AUTOSAR XML (schema 4-3-0)
package /CanCom
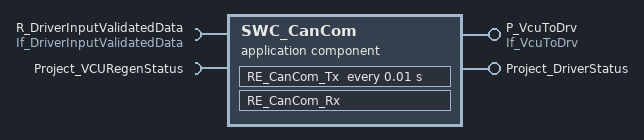
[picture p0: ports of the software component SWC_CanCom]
  application sw component type SWC_CanCom
    provide port P_VcuToDrv: provided-com-specs=[RegenLevel, RegenEnable, LimitReason], provided-interface=If_VcuToDrv
    require port R_DriverInputValidatedData: required-com-specs=[BrakeSw, AccelSw, SocLevel, VehicleSpeed, DriverInputFault], required-interface=If_DriverInputValidatedData
    provide port Project_DriverStatus: provided-interface=Project_DriverStatus
      provided-com-specs:
        data-element=VehicleSpeed, network-representation=compu-method=ISignal_Project_DriverStatus_VehicleSpeed
        data-element=AccelSw, network-representation=compu-method=ISignal_Project_DriverStatus_AccelSw
        data-element=DriverInputFault, network-representation=compu-method=ISignal_Project_DriverStatus_DriverInputFault
        data-element=SocLevel, network-representation=compu-method=ISignal_Project_DriverStatus_SocLevel
        data-element=AliveCounter, network-representation=compu-method=ISignal_Project_DriverStatus_AliveCounter
        data-element=BrakeSw, network-representation=compu-method=ISignal_Project_DriverStatus_BrakeSw
    require port Project_VCURegenStatus: required-interface=Project_VCURegenStatus
      required-com-specs:
        data-element=RegenEnable, network-representation=compu-method=ISignal_Project_VCURegenStatus_RegenEnable
        data-element=LimitReason, network-representation=compu-method=ISignal_Project_VCURegenStatus_LimitReason
        data-element=RegenLevel, network-representation=compu-method=ISignal_Project_VCURegenStatus_RegenLevel
    behavior InternalBehavior
      timing event TE_RE_CanCom_Tx: start-on-event=RE_CanCom_Tx, period=0.01
      data received event DRE_RE_CanCom_Rx_Project_VCURegenStatus_RegenEnable: start-on-event=RE_CanCom_Rx, data=Project_VCURegenStatus.RegenEnable
      data received event DRE_RE_CanCom_Rx_Project_VCURegenStatus_LimitReason: start-on-event=RE_CanCom_Rx, data=Project_VCURegenStatus.LimitReason
      data received event DRE_RE_CanCom_Rx_Project_VCURegenStatus_RegenLevel: start-on-event=RE_CanCom_Rx, data=Project_VCURegenStatus.RegenLevel
      runnable RE_CanCom_Tx: symbol=CanCom_Tx_func
        data-receive-point-by-arguments:
          5 x access, all with scope=COMMUNICATION-INTER-ECU:
            DRPBA_RE_CanCom_Tx_R_DriverInputValidatedData_AccelSw: accessed-variable=R_DriverInputValidatedData.AccelSw
            DRPBA_RE_CanCom_Tx_R_DriverInputValidatedData_BrakeSw: accessed-variable=R_DriverInputValidatedData.BrakeSw
            DRPBA_RE_CanCom_Tx_R_DriverInputValidatedData_DriverInputFault: accessed-variable=R_DriverInputValidatedData.DriverInputFault
            DRPBA_RE_CanCom_Tx_R_DriverInputValidatedData_SocLevel: accessed-variable=R_DriverInputValidatedData.SocLevel
            DRPBA_RE_CanCom_Tx_R_DriverInputValidatedData_VehicleSpeed: accessed-variable=R_DriverInputValidatedData.VehicleSpeed
        data-send-points:
          9 x access, all with scope=COMMUNICATION-INTER-ECU:
            DSP_RE_CanCom_Tx_Project_DriverStatus_AccelSw: accessed-variable=Project_DriverStatus.AccelSw
            DSP_RE_CanCom_Tx_Project_DriverStatus_AliveCounter: accessed-variable=Project_DriverStatus.AliveCounter
            DSP_RE_CanCom_Tx_Project_DriverStatus_BrakeSw: accessed-variable=Project_DriverStatus.BrakeSw
            DSP_RE_CanCom_Tx_Project_DriverStatus_DriverInputFault: accessed-variable=Project_DriverStatus.DriverInputFault
            DSP_RE_CanCom_Tx_Project_DriverStatus_SocLevel: accessed-variable=Project_DriverStatus.SocLevel
            DSP_RE_CanCom_Tx_Project_DriverStatus_VehicleSpeed: accessed-variable=Project_DriverStatus.VehicleSpeed
            DSP_RE_CanCom_Tx_P_VcuToDrv_LimitReason: accessed-variable=P_VcuToDrv.LimitReason
            DSP_RE_CanCom_Tx_P_VcuToDrv_RegenEnable: accessed-variable=P_VcuToDrv.RegenEnable
            DSP_RE_CanCom_Tx_P_VcuToDrv_RegenLevel: accessed-variable=P_VcuToDrv.RegenLevel
      runnable RE_CanCom_Rx: symbol=CanCom_Rx_func
        data-receive-point-by-arguments:
          8 x access, all with scope=COMMUNICATION-INTER-ECU:
            DRPBA_RE_CanCom_Rx_Project_VCURegenStatus_LimitReason: accessed-variable=Project_VCURegenStatus.LimitReason
            DRPBA_RE_CanCom_Rx_Project_VCURegenStatus_RegenEnable: accessed-variable=Project_VCURegenStatus.RegenEnable
            DRPBA_RE_CanCom_Rx_Project_VCURegenStatus_RegenLevel: accessed-variable=Project_VCURegenStatus.RegenLevel
            DRPBA_RE_CanCom_Rx_R_DriverInputValidatedData_AccelSw: accessed-variable=R_DriverInputValidatedData.AccelSw
            DRPBA_RE_CanCom_Rx_R_DriverInputValidatedData_BrakeSw: accessed-variable=R_DriverInputValidatedData.BrakeSw
            DRPBA_RE_CanCom_Rx_R_DriverInputValidatedData_DriverInputFault: accessed-variable=R_DriverInputValidatedData.DriverInputFault
            DRPBA_RE_CanCom_Rx_R_DriverInputValidatedData_SocLevel: accessed-variable=R_DriverInputValidatedData.SocLevel
            DRPBA_RE_CanCom_Rx_R_DriverInputValidatedData_VehicleSpeed: accessed-variable=R_DriverInputValidatedData.VehicleSpeed
        data-send-points:
          access DSP_RE_CanCom_Rx_P_VcuToDrv_LimitReason: accessed-variable=P_VcuToDrv.LimitReason, scope=COMMUNICATION-INTER-ECU
          access DSP_RE_CanCom_Rx_P_VcuToDrv_RegenEnable: accessed-variable=P_VcuToDrv.RegenEnable, scope=COMMUNICATION-INTER-ECU
          access DSP_RE_CanCom_Rx_P_VcuToDrv_RegenLevel: accessed-variable=P_VcuToDrv.RegenLevel, scope=COMMUNICATION-INTER-ECU
